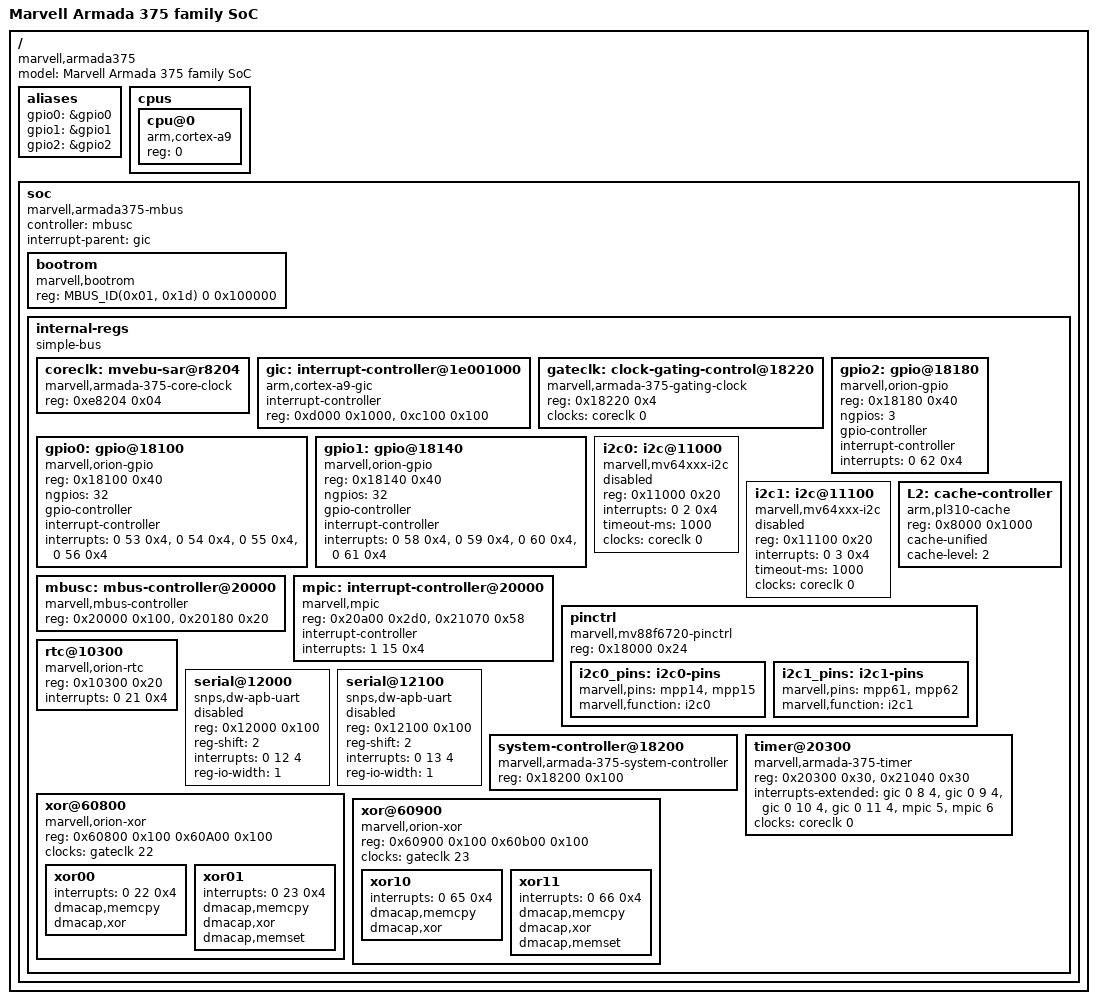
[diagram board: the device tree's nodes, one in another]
/*
 * Device Tree Include file for Marvell Armada 375 family SoC
 *
 * Copyright (C) 2013 Marvell
 *
 * Lior Amsalem <alior@marvell.com>
 * Gregory CLEMENT <gregory.clement@free-electrons.com>
 * Thomas Petazzoni <thomas.petazzoni@free-electrons.com>
 *
 * This file is licensed under the terms of the GNU General Public
 * License version 2.  This program is licensed "as is" without any
 * warranty of any kind, whether express or implied.
 *
 * Contains definitions specific to the Armada 375 SoC that are not
 * common to all Armada SoCs.
 */

/include/ "skeleton.dtsi"

#define MBUS_ID(target,attributes) (((target) << 24) | ((attributes) << 16))

/ {
	model = "Marvell Armada 375 family SoC";
	compatible = "marvell,armada375";

	aliases {
		gpio0 = &gpio0;
		gpio1 = &gpio1;
		gpio2 = &gpio2;
	};

	cpus {
		#address-cells = <1>;
		#size-cells = <0>;
		cpu@0 {
			device_type = "cpu";
			compatible = "arm,cortex-a9";
			reg = <0>;
		};
	};

	soc {
		compatible = "marvell,armada375-mbus", "simple-bus";
		#address-cells = <2>;
		#size-cells = <1>;
		controller = <&mbusc>;
		interrupt-parent = <&gic>;

		bootrom {
			compatible = "marvell,bootrom";
			reg = <MBUS_ID(0x01, 0x1d) 0 0x100000>;
		};

		internal-regs {
			compatible = "simple-bus";
			#address-cells = <1>;
			#size-cells = <1>;
			ranges = <0 MBUS_ID(0xf0, 0x01) 0 0x100000>;

			coreclk: mvebu-sar@r8204 {
				compatible = "marvell,armada-375-core-clock";
				reg = <0xe8204 0x04>;
				#clock-cells = <1>;
			};

			gic: interrupt-controller@1e001000 {
				compatible = "arm,cortex-a9-gic";
				#interrupt-cells = <3>;
				#size-cells = <0>;
				interrupt-controller;
				reg = <0xd000 0x1000>,
				      <0xc100 0x100>;
			};

			gateclk: clock-gating-control@18220 {
				compatible = "marvell,armada-375-gating-clock";
				reg = <0x18220 0x4>;
				clocks = <&coreclk 0>;
				#clock-cells = <1>;
			};

			gpio0: gpio@18100 {
				compatible = "marvell,orion-gpio";
				reg = <0x18100 0x40>;
				ngpios = <32>;
				gpio-controller;
				#gpio-cells = <2>;
				interrupt-controller;
				#interrupt-cells = <2>;
				interrupts = <0 53 0x4>, <0 54 0x4>,
					     <0 55 0x4>, <0 56 0x4>;
			};

			gpio1: gpio@18140 {
				compatible = "marvell,orion-gpio";
				reg = <0x18140 0x40>;
				ngpios = <32>;
				gpio-controller;
				#gpio-cells = <2>;
				interrupt-controller;
				#interrupt-cells = <2>;
				interrupts = <0 58 0x4>, <0 59 0x4>,
					     <0 60 0x4>, <0 61 0x4>;
			};

			gpio2: gpio@18180 {
				compatible = "marvell,orion-gpio";
				reg = <0x18180 0x40>;
				ngpios = <3>;
				gpio-controller;
				#gpio-cells = <2>;
				interrupt-controller;
				#interrupt-cells = <2>;
				interrupts = <0 62 0x4>;
			};

			i2c0: i2c@11000 {
				compatible = "marvell,mv64xxx-i2c";
				reg = <0x11000 0x20>;
				#address-cells = <1>;
				#size-cells = <0>;
				interrupts = <0 2 0x4>;
				timeout-ms = <1000>;
				clocks = <&coreclk 0>;
				status = "disabled";
			};

			i2c1: i2c@11100 {
				compatible = "marvell,mv64xxx-i2c";
				reg = <0x11100 0x20>;
				#address-cells = <1>;
				#size-cells = <0>;
				interrupts = <0 3 0x4>;
				timeout-ms = <1000>;
				clocks = <&coreclk 0>;
				status = "disabled";
			};

			L2: cache-controller {
				compatible = "arm,pl310-cache";
				reg = <0x8000 0x1000>;
				cache-unified;
				cache-level = <2>;
			};

			mbusc: mbus-controller@20000 {
				compatible = "marvell,mbus-controller";
				reg = <0x20000 0x100>, <0x20180 0x20>;
			};

			mpic: interrupt-controller@20000 {
				compatible = "marvell,mpic";
				reg = <0x20a00 0x2d0>, <0x21070 0x58>;
				#interrupt-cells = <1>;
				#size-cells = <1>;
				interrupt-controller;
				interrupts = <1 15 0x4>;
			};

			pinctrl {
				compatible = "marvell,mv88f6720-pinctrl";
				reg = <0x18000 0x24>;

				i2c0_pins: i2c0-pins {
					marvell,pins = "mpp14",  "mpp15";
					marvell,function = "i2c0";
				};

				i2c1_pins: i2c1-pins {
					marvell,pins = "mpp61",  "mpp62";
					marvell,function = "i2c1";
				};
			};

			rtc@10300 {
				compatible = "marvell,orion-rtc";
				reg = <0x10300 0x20>;
				interrupts = <0 21 0x4>;
			};

			serial@12000 {
				compatible = "snps,dw-apb-uart";
				reg = <0x12000 0x100>;
				reg-shift = <2>;
				interrupts = <0 12 4>;
				reg-io-width = <1>;
				status = "disabled";
			};

			serial@12100 {
				compatible = "snps,dw-apb-uart";
				reg = <0x12100 0x100>;
				reg-shift = <2>;
				interrupts = <0 13 4>;
				reg-io-width = <1>;
				status = "disabled";
			};

			system-controller@18200 {
				compatible = "marvell,armada-375-system-controller";
				reg = <0x18200 0x100>;
			};

			timer@20300 {
				compatible = "marvell,armada-375-timer";
				reg = <0x20300 0x30>, <0x21040 0x30>;
				interrupts-extended = <&gic  0  8 4>,
						      <&gic  0  9 4>,
						      <&gic  0 10 4>,
						      <&gic  0 11 4>,
						      <&mpic 5>,
						      <&mpic 6>;
				clocks = <&coreclk 0>;
			};

			xor@60800 {
				compatible = "marvell,orion-xor";
				reg = <0x60800 0x100
				       0x60A00 0x100>;
				clocks = <&gateclk 22>;
				status = "okay";

				xor00 {
					interrupts = <0 22 0x4>;
					dmacap,memcpy;
					dmacap,xor;
				};
				xor01 {
					interrupts = <0 23 0x4>;
					dmacap,memcpy;
					dmacap,xor;
					dmacap,memset;
				};
			};

			xor@60900 {
				compatible = "marvell,orion-xor";
				reg = <0x60900 0x100
				       0x60b00 0x100>;
				clocks = <&gateclk 23>;
				status = "okay";

				xor10 {
					interrupts = <0 65 0x4>;
					dmacap,memcpy;
					dmacap,xor;
				};
				xor11 {
					interrupts = <0 66 0x4>;
					dmacap,memcpy;
					dmacap,xor;
					dmacap,memset;
				};
			};
		};
	};
};
